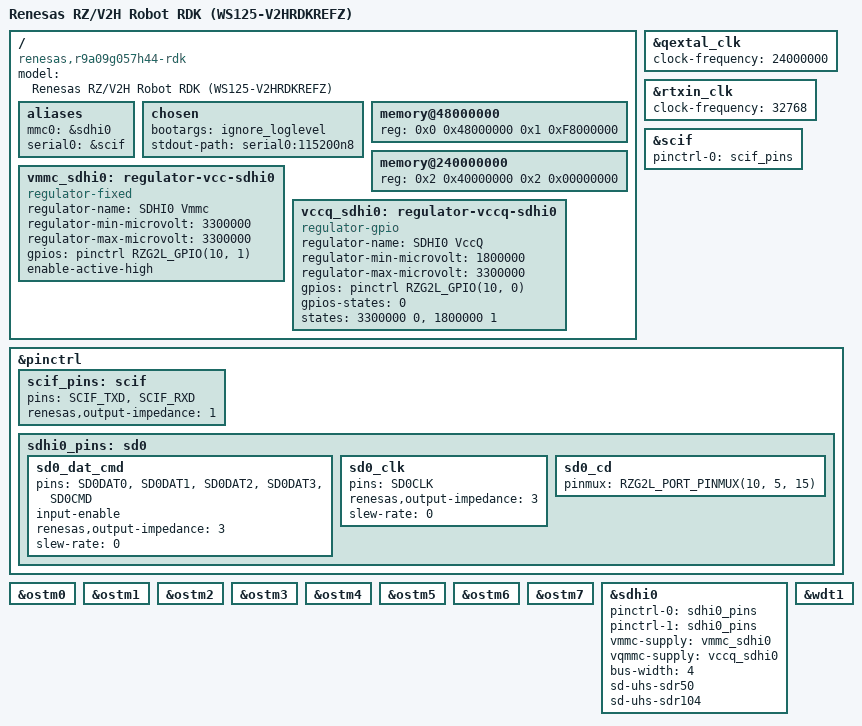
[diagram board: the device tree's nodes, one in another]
// SPDX-License-Identifier: (GPL-2.0-only OR BSD-2-Clause)
/*
 * Device Tree Source for the Renesas RZ/V2H Robot RDK (WS125-V2HRDKREFZ)
 *
 * Avocado first cut: derived from the cip 6.12 r9a09g057h44-rzv2h-evk.dts, with
 * the microSD switched to SD0/SDHI0 per the RDK hardware manual
 * (R16UH0052EU0100 section 3.9) and the console kept on SCIF (ttySC0, the RDK's
 * FT234XD USB-UART).
 *
 * SD0 pin ports resolved from the RZ/V2H EVK hardware manual (R12UZ0147EJ0130
 * section 1.3.5) cross-referenced with the cip 6.12 EVK dts: SoC port PA maps to
 * mainline rzg2l port 10 (ports P0..P9 == 0..9, PA == 10, PB == 11), so the
 * vendor's RZV2H_*(A, n) values become RZG2L_*(10, n) with pin and function
 * indices unchanged. Confirmed against the SoC manual R01UH1032EJ Table 1.2-3:
 * PA5 Func15 = SD0CD, PA1 Func1 = SD0PWEN (vmmc), PA0 Func1 = SD0IOVS (vccq).
 * Only actual card detection remains to verify on a board.
 *
 * TODO(port from vendor dts): CAN-FD x2, 40-pin RasPi GPIO header, PCIe 3.0 RC,
 * USB3.2 x2, GbE eth0 (RGMII PHY 0022.1640) are not yet ported. Translate their
 * pins with the same mapping (PA->10, PB->11; ports 0-9 unchanged).
 *
 * Copyright (C) 2024 Renesas Electronics Corp.
 */

/dts-v1/;

#include <dt-bindings/pinctrl/rzg2l-pinctrl.h>
#include <dt-bindings/gpio/gpio.h>
#include "r9a09g057.dtsi"

/ {
	model = "Renesas RZ/V2H Robot RDK (WS125-V2HRDKREFZ)";
	compatible = "renesas,r9a09g057h44-rdk", "renesas,r9a09g057h44", "renesas,r9a09g057";

	aliases {
		mmc0 = &sdhi0;
		serial0 = &scif;
	};

	chosen {
		bootargs = "ignore_loglevel";
		stdout-path = "serial0:115200n8";
	};

	memory@48000000 {
		device_type = "memory";
		/* first 128MB is reserved for secure area. */
		reg = <0x0 0x48000000 0x1 0xF8000000>;
	};

	memory@240000000 {
		device_type = "memory";
		reg = <0x2 0x40000000 0x2 0x00000000>;
	};

	vmmc_sdhi0: regulator-vcc-sdhi0 {
		compatible = "regulator-fixed";
		regulator-name = "SDHI0 Vmmc";
		regulator-min-microvolt = <3300000>;
		regulator-max-microvolt = <3300000>;
		/* SD0PWEN = PA1 (vendor RZV2H_GPIO(A, 1)). */
		gpios = <&pinctrl RZG2L_GPIO(10, 1) GPIO_ACTIVE_HIGH>;
		enable-active-high;
	};

	vccq_sdhi0: regulator-vccq-sdhi0 {
		compatible = "regulator-gpio";
		regulator-name = "SDHI0 VccQ";
		regulator-min-microvolt = <1800000>;
		regulator-max-microvolt = <3300000>;
		/* SD0IOVS = PA0 (vendor RZV2H_GPIO(A, 0)). */
		gpios = <&pinctrl RZG2L_GPIO(10, 0) GPIO_ACTIVE_HIGH>;
		gpios-states = <0>;
		states = <3300000 0>, <1800000 1>;
	};
};

&qextal_clk {
	clock-frequency = <24000000>;
};

&rtxin_clk {
	clock-frequency = <32768>;
};

&scif {
	pinctrl-0 = <&scif_pins>;
	pinctrl-names = "default";
	status = "okay";
};

&pinctrl {
	scif_pins: scif {
		pins = "SCIF_TXD", "SCIF_RXD";
		renesas,output-impedance = <1>;
	};

	sdhi0_pins: sd0 {
		sd0_dat_cmd {
			pins = "SD0DAT0", "SD0DAT1", "SD0DAT2", "SD0DAT3", "SD0CMD";
			input-enable;
			renesas,output-impedance = <3>;
			slew-rate = <0>;
		};

		sd0_clk {
			pins = "SD0CLK";
			renesas,output-impedance = <3>;
			slew-rate = <0>;
		};

		sd0_cd {
			/* SD0_CD = PA5 (vendor RZV2H_PORT_PINMUX(A, 5, 15)). */
			pinmux = <RZG2L_PORT_PINMUX(10, 5, 15)>;
		};
	};
};

&ostm0 { status = "okay"; };
&ostm1 { status = "okay"; };
&ostm2 { status = "okay"; };
&ostm3 { status = "okay"; };
&ostm4 { status = "okay"; };
&ostm5 { status = "okay"; };
&ostm6 { status = "okay"; };
&ostm7 { status = "okay"; };

&sdhi0 {
	pinctrl-0 = <&sdhi0_pins>;
	pinctrl-1 = <&sdhi0_pins>;
	pinctrl-names = "default", "state_uhs";
	vmmc-supply = <&vmmc_sdhi0>;
	vqmmc-supply = <&vccq_sdhi0>;
	bus-width = <4>;
	sd-uhs-sdr50;
	sd-uhs-sdr104;
	status = "okay";
};

&wdt1 {
	status = "okay";
};
